VERSION ""

NS_ :

BS_:

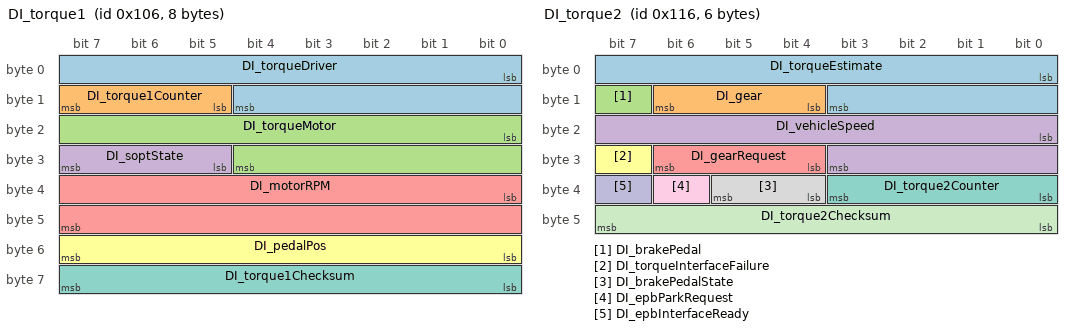
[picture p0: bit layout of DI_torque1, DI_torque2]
BO_ 262 DI_torque1: 8 DI
 SG_ DI_torqueDriver : 0|13@1- (0.25,0) [-750|750] "Nm"  NEO
 SG_ DI_torque1Counter : 13|3@1+ (1,0) [0|0] ""  NEO
 SG_ DI_torqueMotor : 16|13@1- (0.25,0) [-750|750] "Nm"  NEO
 SG_ DI_soptState : 29|3@1+ (1,0) [0|0] ""  NEO
 SG_ DI_motorRPM : 32|16@1- (1,0) [-17000|17000] "RPM"  NEO
 SG_ DI_pedalPos : 48|8@1+ (0.4,0) [0|100] "%"  NEO
 SG_ DI_torque1Checksum : 56|8@1+ (1,0) [0|0] ""  NEO

BO_ 278 DI_torque2: 6 DI
 SG_ DI_torqueEstimate : 0|12@1- (0.5,0) [-750|750] "Nm" NEO
 SG_ DI_gear : 12|3@1+ (1,0) [0|0] "" NEO
 SG_ DI_brakePedal : 15|1@1+ (1,0) [0|0] "" NEO
 SG_ DI_vehicleSpeed : 16|12@1+ (0.05,-25) [-25|179.75] "MPH" NEO
 SG_ DI_gearRequest : 28|3@1+ (1,0) [0|0] "" NEO
 SG_ DI_torqueInterfaceFailure : 31|1@1+ (1,0) [0|0] "" NEO
 SG_ DI_torque2Counter : 32|4@1+ (1,0) [0|0] "" NEO
 SG_ DI_brakePedalState : 36|2@1+ (1,0) [0|0] "" NEO
 SG_ DI_epbParkRequest : 38|1@1+ (1,0) [0|0] "" NEO
 SG_ DI_epbInterfaceReady : 39|1@1+ (1,0) [0|0] "" NEO
 SG_ DI_torque2Checksum : 40|8@1+ (1,0) [0|0] "" NEO

BO_ 504 BrakeMessage: 8 XXX
 SG_ driverBrakeStatus : 2|2@1+ (1,0) [0|3] "" XXX

BO_ 568 STW_ACTN_RQ: 8 STW
 SG_ SpdCtrlLvr_Stat : 0|6@1+ (1,0) [0|0] "" NEO
 SG_ VSL_Enbl_Rq : 6|1@1+ (1,0) [0|0] "" NEO
 SG_ SpdCtrlLvrStat_Inv : 7|1@1+ (1,0) [0|0] "" NEO
 SG_ DTR_Dist_Rq : 8|8@1+ (1,0) [0|200] "" NEO
 SG_ TurnIndLvr_Stat : 16|2@1+ (1,0) [0|0] "" NEO
 SG_ HiBmLvr_Stat : 18|2@1+ (1,0) [0|0] "" NEO
 SG_ WprWashSw_Psd : 20|2@1+ (1,0) [0|0] "" NEO
 SG_ WprWash_R_Sw_Posn_V2 : 22|2@1+ (1,0) [0|0] "" NEO
 SG_ StW_Lvr_Stat : 24|3@1+ (1,0) [0|0] "" NEO
 SG_ StW_Cond_Flt : 27|1@1+ (1,0) [0|0] "" NEO
 SG_ StW_Cond_Psd : 28|2@1+ (1,0) [0|0] "" NEO
 SG_ HrnSw_Psd : 30|2@1+ (1,0) [0|0] "" NEO
 SG_ StW_Sw00_Psd : 32|1@1+ (1,0) [0|0] "" NEO
 SG_ StW_Sw01_Psd : 33|1@1+ (1,0) [0|0] "" NEO
 SG_ StW_Sw02_Psd : 34|1@1+ (1,0) [0|0] "" NEO
 SG_ StW_Sw03_Psd : 35|1@1+ (1,0) [0|0] "" NEO
 SG_ StW_Sw04_Psd : 36|1@1+ (1,0) [0|0] "" NEO
 SG_ StW_Sw05_Psd : 37|1@1+ (1,0) [0|0] "" NEO
 SG_ StW_Sw06_Psd : 38|1@1+ (1,0) [0|0] "" NEO
 SG_ StW_Sw07_Psd : 39|1@1+ (1,0) [0|0] "" NEO
 SG_ StW_Sw08_Psd : 40|1@1+ (1,0) [0|0] "" NEO
 SG_ StW_Sw09_Psd : 41|1@1+ (1,0) [0|0] "" NEO
 SG_ StW_Sw10_Psd : 42|1@1+ (1,0) [0|0] "" NEO
 SG_ StW_Sw11_Psd : 43|1@1+ (1,0) [0|0] "" NEO
 SG_ StW_Sw12_Psd : 44|1@1+ (1,0) [0|0] "" NEO
 SG_ StW_Sw13_Psd : 45|1@1+ (1,0) [0|0] "" NEO
 SG_ StW_Sw14_Psd : 46|1@1+ (1,0) [0|0] "" NEO
 SG_ StW_Sw15_Psd : 47|1@1+ (1,0) [0|0] "" NEO
 SG_ WprSw6Posn : 48|3@1+ (1,0) [0|0] "" NEO
 SG_ MC_STW_ACTN_RQ : 52|4@1+ (1,0) [0|15] "" NEO
 SG_ CRC_STW_ACTN_RQ : 56|8@1+ (1,0) [0|0] "" NEO

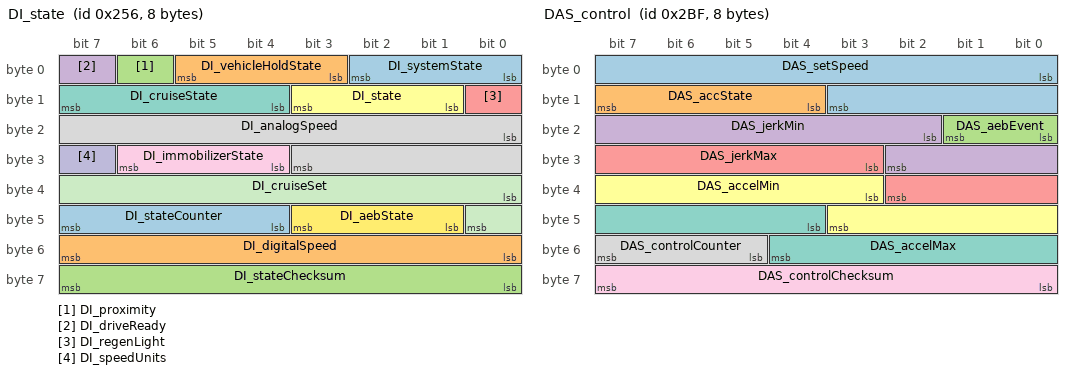
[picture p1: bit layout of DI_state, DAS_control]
BO_ 598 DI_state: 8 DI
 SG_ DI_systemState : 0|3@1+ (1,0) [0|0] ""  NEO
 SG_ DI_vehicleHoldState : 3|3@1+ (1,0) [0|0] ""  NEO
 SG_ DI_proximity : 6|1@1+ (1,0) [0|0] ""  NEO
 SG_ DI_driveReady : 7|1@1+ (1,0) [0|0] ""  NEO
 SG_ DI_regenLight : 8|1@1+ (1,0) [0|0] ""  NEO
 SG_ DI_state : 9|3@1+ (1,0) [0|0] ""  NEO
 SG_ DI_cruiseState : 12|4@1+ (1,0) [0|0] ""  NEO
 SG_ DI_analogSpeed : 16|12@1+ (0.1,0) [0|150] "speed"  NEO
 SG_ DI_immobilizerState : 28|3@1+ (1,0) [0|0] ""  NEO
 SG_ DI_speedUnits : 31|1@1+ (1,0) [0|1] ""  NEO
 SG_ DI_cruiseSet : 32|9@1+ (0.5,0) [0|255.5] "speed"  NEO
 SG_ DI_aebState : 41|3@1+ (1,0) [0|0] ""  NEO
 SG_ DI_stateCounter : 44|4@1+ (1,0) [0|0] ""  NEO
 SG_ DI_digitalSpeed : 48|8@1+ (1,0) [0|250] ""  NEO
 SG_ DI_stateChecksum : 56|8@1+ (1,0) [0|0] ""  NEO

BO_ 703 DAS_control: 8 GTW
 SG_ DAS_setSpeed : 0|12@1+ (0.1,0) [0|409.4] "kph" DI,PM,APS
 SG_ DAS_accState : 12|4@1+ (1,0) [0|0] "" DI,PM,APS
 SG_ DAS_aebEvent : 16|2@1+ (1,0) [0|3] "" DI,PM,APS
 SG_ DAS_jerkMin : 18|9@1+ (0.03,-15.232) [-15.232|0.098] "m/s^3" DI,PM,APS
 SG_ DAS_jerkMax : 27|8@1+ (0.059,0) [0|15.045] "m/s^3" DI,PM,APS
 SG_ DAS_accelMin : 35|9@1+ (0.04,-15) [-15|5.44] "m/s^2" DI,PM,APS
 SG_ DAS_accelMax : 44|9@1+ (0.04,-15) [-15|5.44] "m/s^2" DI,PM,APS
 SG_ DAS_controlCounter : 53|3@1+ (1,0) [0|0] "" DI,PM,APS
 SG_ DAS_controlChecksum : 56|8@1+ (1,0) [0|0] "" DI,PM,APS

CM_ "AUTOGENERATED FILE, DO NOT EDIT";

CM_ "Imported file _subaru_preglobal_2015.dbc starts here";
CM_ SG_ 320 Off_Throttle_2 "Less sensitive";
CM_ SG_ 320 Throttle_Body "Throttle related";
CM_ SG_ 328 Gear "15 = P, 14 = R, 0 = N, 1-6=gear";
CM_ SG_ 328 Gear_2 "15 = P, 14 = R, 0 = N, 1-6=gear";
CM_ SG_ 353 Cruise_Button "1 = main, 2 = set shallow, 3 = set deep, 4 = resume shallow, 5 resume deep";
CM_ SG_ 354 RPM "20hz version of Transmission_Engine under Transmission";
CM_ SG_ 359 Sig1Right_Depart "right depart, hill steep and seatbelt disengage";
CM_ SG_ 359 LKAS_Inactive_2017 "1 when not steering, 0 when lkas steering";
CM_ SG_ 359 Sig1Right_Depart_Front "object in front, right depart, hill steep and seatbelt disengage alert ";
CM_ SG_ 359 Left_Depart_Front "warning after acceleration into car in front and left depart";
CM_ SG_ 359 Sig1All_Depart "Left and right depart";
CM_ SG_ 359 Sig2All_Depart "Left and right depart";
CM_ SG_ 359 All_depart_2015 "always 1 on 2017";
CM_ SG_ 604 R_APPROACHING "Faster car approaching in far right lane";
CM_ SG_ 604 L_APPROACHING "Faster car approaching in far left lane";
CM_ SG_ 604 R_RCTA "Rear cross traffic alert, only when in R gear";
CM_ SG_ 604 L_RCTA "Rear cross traffic alert, only when in R gear";
CM_ SG_ 642 COUNTER "Affected by signals";
CM_ SG_ 642 SEATBELT_FL "Driver seatbelt";
CM_ SG_ 880 Steering_Voltage_Flat "receives later than 371";
CM_ SG_ 977 UNITS "0 = Metric, 1 = Imperial";

CM_ "subaru_outback_2019.dbc starts here";

CM_ SG_ 358 Disengage_Alert "seatbelt and steep hill disengage";
CM_ SG_ 358 Cruise_Fault "No engagement until restart";
VAL_ 552 GEAR 1 "P" 2 "R" 3 "N" 4 "D" ;
VAL_ 540 RADAR_HAS_LEAD 0 "NO LEAD" 1 "HAS LEAD" ;
VAL_ 540 RADAR_LEAD_RELATIVE_DISTANCE 0 "NO LEAD" 1 "FARTHEST" 2 "4" 3 "3" 4 "2" 5 "NEAREST" ;
VAL_ 1143 LEFT_BS_STATUS 0 "No object detected" 1 "Object detected in left blindspot" 2 "Object detected in left blindspot with blinker - warning"
